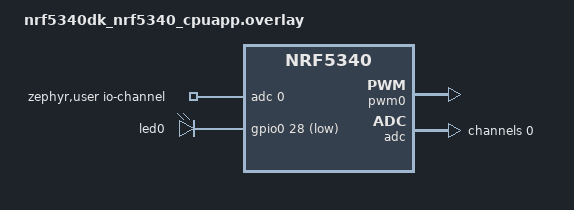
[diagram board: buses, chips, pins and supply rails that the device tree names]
/ {
	zephyr,user {
		io-channels = <&adc 0>;
	};
};

&pwm0 {
    status = "okay";
};

&usbreg {
    status = "disabled";
};

&reset {
    status = "disabled";
};

&led0 {
    gpios = <&gpio0 28 GPIO_ACTIVE_LOW>;
};

&pwm0_default {
    group1 {
        psels = <NRF_PSEL(PWM_OUT0, 0, 28)>;
    };
};

&clock {
    status = "okay";
};

&pwm_led0 {
    pwms = <&pwm0 0 PWM_MSEC(20) 1>;
};

&pwm_led0 {
    pwms = <&pwm0 0 PWM_MSEC(20) 0>;
};

&pwm_led0 {
    pwms = <&pwm0 0 PWM_MSEC(20) 1>;
};

&adc {
	#address-cells = <1>;
	#size-cells = <0>;
	status = "okay";
	channel@0 {
		reg = <0>;
		zephyr,gain = "ADC_GAIN_1_6";
		zephyr,reference = "ADC_REF_INTERNAL";
		zephyr,acquisition-time = <ADC_ACQ_TIME_DEFAULT>;
		zephyr,input-positive = <NRF_SAADC_AIN0>; /* P0.02 for nRF52xx, P0.04 for nRF5340 */
		zephyr,resolution = <12>;
	};
};

